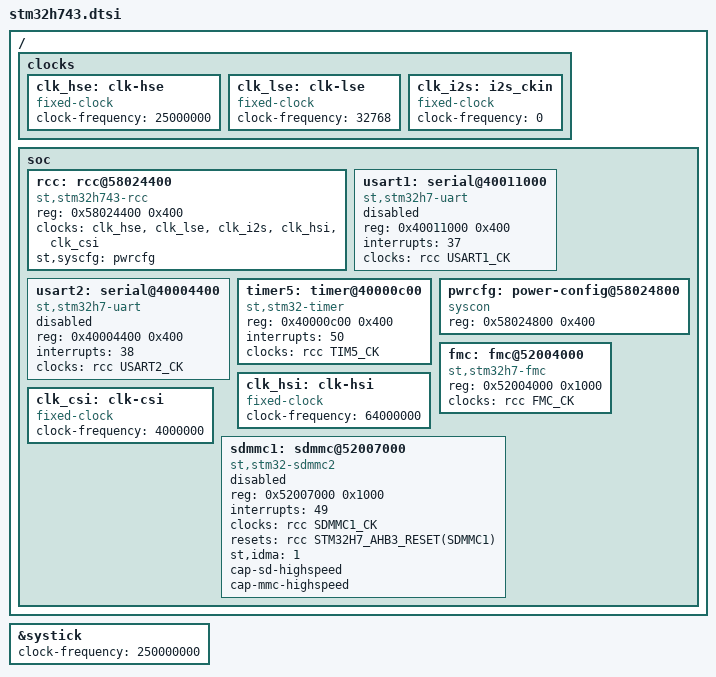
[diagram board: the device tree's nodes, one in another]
/*
 * Copyright 2017 - Alexandre Torgue <alexandre.torgue@st.com>
 *
 * This file is dual-licensed: you can use it either under the terms
 * of the GPL or the X11 license, at your option. Note that this dual
 * licensing only applies to this file, and not this project as a
 * whole.
 *
 *  a) This file is free software; you can redistribute it and/or
 *     modify it under the terms of the GNU General Public License as
 *     published by the Free Software Foundation; either version 2 of the
 *     License, or (at your option) any later version.
 *
 *     This file is distributed in the hope that it will be useful,
 *     but WITHOUT ANY WARRANTY; without even the implied warranty of
 *     MERCHANTABILITY or FITNESS FOR A PARTICULAR PURPOSE.  See the
 *     GNU General Public License for more details.
 *
 * Or, alternatively,
 *
 *  b) Permission is hereby granted, free of charge, to any person
 *     obtaining a copy of this software and associated documentation
 *     files (the "Software"), to deal in the Software without
 *     restriction, including without limitation the rights to use,
 *     copy, modify, merge, publish, distribute, sublicense, and/or
 *     sell copies of the Software, and to permit persons to whom the
 *     Software is furnished to do so, subject to the following
 *     conditions:
 *
 *     The above copyright notice and this permission notice shall be
 *     included in all copies or substantial portions of the Software.
 *
 *     THE SOFTWARE IS PROVIDED "AS IS", WITHOUT WARRANTY OF ANY KIND,
 *     EXPRESS OR IMPLIED, INCLUDING BUT NOT LIMITED TO THE WARRANTIES
 *     OF MERCHANTABILITY, FITNESS FOR A PARTICULAR PURPOSE AND
 *     NONINFRINGEMENT. IN NO EVENT SHALL THE AUTHORS OR COPYRIGHT
 *     HOLDERS BE LIABLE FOR ANY CLAIM, DAMAGES OR OTHER LIABILITY,
 *     WHETHER IN AN ACTION OF CONTRACT, TORT OR OTHERWISE, ARISING
 *     FROM, OUT OF OR IN CONNECTION WITH THE SOFTWARE OR THE USE OR
 *     OTHER DEALINGS IN THE SOFTWARE.
 */

#include "skeleton.dtsi"
#include "armv7-m.dtsi"
#include <dt-bindings/clock/stm32h7-clks.h>
#include <dt-bindings/mfd/stm32h7-rcc.h>

/ {
	clocks {
		clk_hse: clk-hse {
			#clock-cells = <0>;
			compatible = "fixed-clock";
			clock-frequency = <25000000>;
		};

		clk_lse: clk-lse {
			#clock-cells = <0>;
			compatible = "fixed-clock";
			clock-frequency = <32768>;
		};

		clk_i2s: i2s_ckin {
			#clock-cells = <0>;
			compatible = "fixed-clock";
			clock-frequency = <0>;
		};
	};

	soc {
		rcc: rcc@58024400 {
			#clock-cells = <1>;
			#reset-cells = <1>;
			compatible = "st,stm32h743-rcc", "st,stm32-rcc";
			reg = <0x58024400 0x400>;
			clocks = <&clk_hse>, <&clk_lse>, <&clk_i2s>, <&clk_hsi>, <&clk_csi>;
			st,syscfg = <&pwrcfg>;
		};

		usart1: serial@40011000 {
			compatible = "st,stm32h7-uart";
			reg = <0x40011000 0x400>;
			interrupts = <37>;
			status = "disabled";
			clocks = <&rcc USART1_CK>;
		};

		usart2: serial@40004400 {
			compatible = "st,stm32h7-uart";
			reg = <0x40004400 0x400>;
			interrupts = <38>;
			status = "disabled";
			clocks = <&rcc USART2_CK>;
		};

		timer5: timer@40000c00 {
			compatible = "st,stm32-timer";
			reg = <0x40000c00 0x400>;
			interrupts = <50>;
			clocks = <&rcc TIM5_CK>;
		};

		pwrcfg: power-config@58024800 {
			compatible = "syscon";
			reg = <0x58024800 0x400>;
		};

		fmc: fmc@52004000 {
			compatible = "st,stm32h7-fmc";
			reg = <0x52004000 0x1000>;
			clocks = <&rcc FMC_CK>;
		};

		clk_hsi: clk-hsi {
			#clock-cells = <0>;
			compatible = "fixed-clock";
			clock-frequency = <64000000>;
		};

		clk_csi: clk-csi {
			#clock-cells = <0>;
			compatible = "fixed-clock";
			clock-frequency = <4000000>;
		};

		sdmmc1: sdmmc@52007000 {
			compatible = "st,stm32-sdmmc2";
			reg = <0x52007000 0x1000>;
			interrupts = <49>;
			clocks = <&rcc SDMMC1_CK>;
			resets = <&rcc STM32H7_AHB3_RESET(SDMMC1)>;
			st,idma = <1>;
			cap-sd-highspeed;
			cap-mmc-highspeed;
			status = "disabled";
		};
	};
};

&systick {
	clock-frequency = <250000000>;
	status = "okay";
};
